# DA14531 register map
Vendor: Dialog; Series: DA14531; File version: 1.2
CPU: CM0 r1p0, little endian, MPU, FPU, 3 interrupt priority bits
Registers are 16-bit, read-write, reset 0x0 unless marked. A register's access mark holds for its fields unless they carry their own. Offsets are from the block's base; [hi:lo] are bit positions; {n}, {i} and the like mark numbered series.

## RFCU_POWER — RFCU_POWER registers
Base 0x40001200
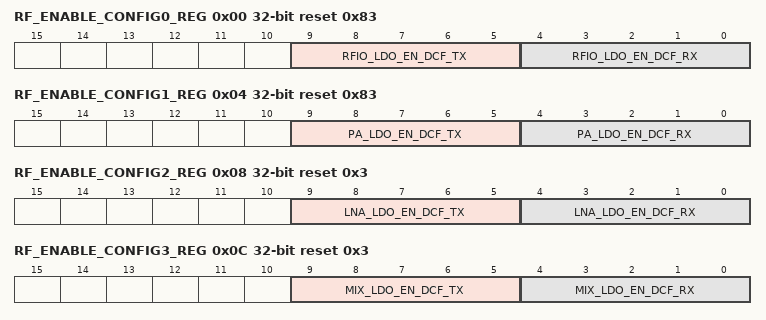
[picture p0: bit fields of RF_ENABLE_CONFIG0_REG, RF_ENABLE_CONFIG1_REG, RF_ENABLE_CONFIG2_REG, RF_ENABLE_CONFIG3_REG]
0x00 RF_ENABLE_CONFIG0_REG 32-bit reset 0x83
  [9:5] RFIO_LDO_EN_DCF_TX, [4:0] RFIO_LDO_EN_DCF_RX
0x04 RF_ENABLE_CONFIG1_REG 32-bit reset 0x83
  [9:5] PA_LDO_EN_DCF_TX, [4:0] PA_LDO_EN_DCF_RX
0x08 RF_ENABLE_CONFIG2_REG 32-bit reset 0x3
  [9:5] LNA_LDO_EN_DCF_TX, [4:0] LNA_LDO_EN_DCF_RX
0x0C RF_ENABLE_CONFIG3_REG 32-bit reset 0x3
  [9:5] MIX_LDO_EN_DCF_TX, [4:0] MIX_LDO_EN_DCF_RX
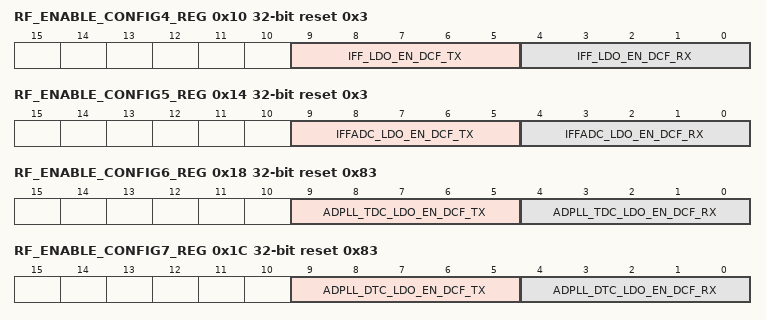
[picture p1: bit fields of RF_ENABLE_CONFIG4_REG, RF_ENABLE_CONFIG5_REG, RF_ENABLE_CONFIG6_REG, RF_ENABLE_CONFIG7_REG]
0x10 RF_ENABLE_CONFIG4_REG 32-bit reset 0x3
  [9:5] IFF_LDO_EN_DCF_TX, [4:0] IFF_LDO_EN_DCF_RX
0x14 RF_ENABLE_CONFIG5_REG 32-bit reset 0x3
  [9:5] IFFADC_LDO_EN_DCF_TX, [4:0] IFFADC_LDO_EN_DCF_RX
0x18 RF_ENABLE_CONFIG6_REG 32-bit reset 0x83
  [9:5] ADPLL_TDC_LDO_EN_DCF_TX, [4:0] ADPLL_TDC_LDO_EN_DCF_RX
0x1C RF_ENABLE_CONFIG7_REG 32-bit reset 0x83
  [9:5] ADPLL_DTC_LDO_EN_DCF_TX, [4:0] ADPLL_DTC_LDO_EN_DCF_RX
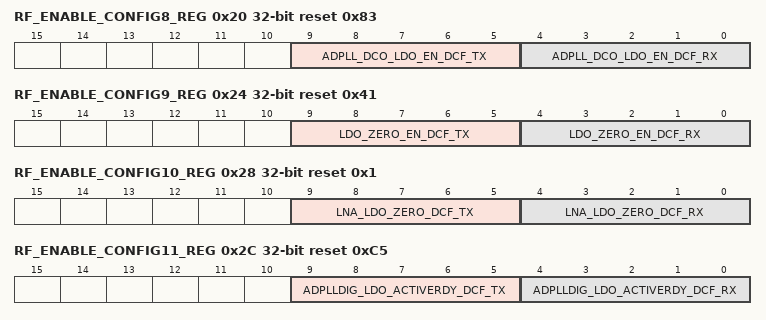
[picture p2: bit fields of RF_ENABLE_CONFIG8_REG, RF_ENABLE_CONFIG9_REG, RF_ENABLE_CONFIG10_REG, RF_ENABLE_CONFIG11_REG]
0x20 RF_ENABLE_CONFIG8_REG 32-bit reset 0x83
  [9:5] ADPLL_DCO_LDO_EN_DCF_TX, [4:0] ADPLL_DCO_LDO_EN_DCF_RX
0x24 RF_ENABLE_CONFIG9_REG 32-bit reset 0x41
  [9:5] LDO_ZERO_EN_DCF_TX, [4:0] LDO_ZERO_EN_DCF_RX
0x28 RF_ENABLE_CONFIG10_REG 32-bit reset 0x1
  [9:5] LNA_LDO_ZERO_DCF_TX, [4:0] LNA_LDO_ZERO_DCF_RX
0x2C RF_ENABLE_CONFIG11_REG 32-bit reset 0xC5
  [9:5] ADPLLDIG_LDO_ACTIVERDY_DCF_TX, [4:0] ADPLLDIG_LDO_ACTIVERDY_DCF_RX
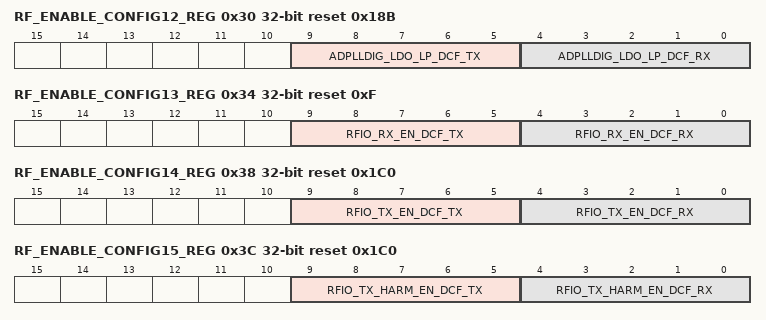
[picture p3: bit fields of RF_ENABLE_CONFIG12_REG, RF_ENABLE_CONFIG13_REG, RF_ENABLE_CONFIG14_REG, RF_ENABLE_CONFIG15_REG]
0x30 RF_ENABLE_CONFIG12_REG 32-bit reset 0x18B
  [9:5] ADPLLDIG_LDO_LP_DCF_TX, [4:0] ADPLLDIG_LDO_LP_DCF_RX
0x34 RF_ENABLE_CONFIG13_REG 32-bit reset 0xF
  [9:5] RFIO_RX_EN_DCF_TX, [4:0] RFIO_RX_EN_DCF_RX
0x38 RF_ENABLE_CONFIG14_REG 32-bit reset 0x1C0
  [9:5] RFIO_TX_EN_DCF_TX, [4:0] RFIO_TX_EN_DCF_RX
0x3C RF_ENABLE_CONFIG15_REG 32-bit reset 0x1C0
  [9:5] RFIO_TX_HARM_EN_DCF_TX, [4:0] RFIO_TX_HARM_EN_DCF_RX
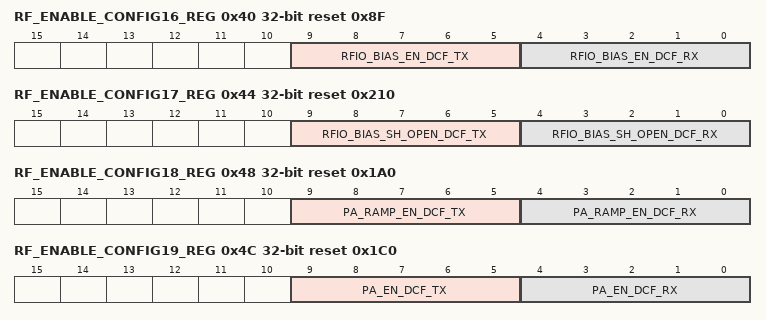
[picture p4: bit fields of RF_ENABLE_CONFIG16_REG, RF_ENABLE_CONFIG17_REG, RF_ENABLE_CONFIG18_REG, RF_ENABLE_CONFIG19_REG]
0x40 RF_ENABLE_CONFIG16_REG 32-bit reset 0x8F
  [9:5] RFIO_BIAS_EN_DCF_TX, [4:0] RFIO_BIAS_EN_DCF_RX
0x44 RF_ENABLE_CONFIG17_REG 32-bit reset 0x210
  [9:5] RFIO_BIAS_SH_OPEN_DCF_TX, [4:0] RFIO_BIAS_SH_OPEN_DCF_RX
0x48 RF_ENABLE_CONFIG18_REG 32-bit reset 0x1A0
  [9:5] PA_RAMP_EN_DCF_TX, [4:0] PA_RAMP_EN_DCF_RX
0x4C RF_ENABLE_CONFIG19_REG 32-bit reset 0x1C0
  [9:5] PA_EN_DCF_TX, [4:0] PA_EN_DCF_RX
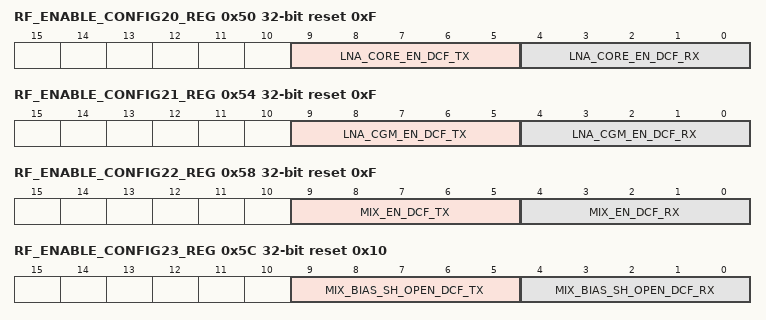
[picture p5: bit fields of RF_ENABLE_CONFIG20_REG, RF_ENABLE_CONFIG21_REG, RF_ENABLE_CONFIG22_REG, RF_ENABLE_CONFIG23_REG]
0x50 RF_ENABLE_CONFIG20_REG 32-bit reset 0xF
  [9:5] LNA_CORE_EN_DCF_TX, [4:0] LNA_CORE_EN_DCF_RX
0x54 RF_ENABLE_CONFIG21_REG 32-bit reset 0xF
  [9:5] LNA_CGM_EN_DCF_TX, [4:0] LNA_CGM_EN_DCF_RX
0x58 RF_ENABLE_CONFIG22_REG 32-bit reset 0xF
  [9:5] MIX_EN_DCF_TX, [4:0] MIX_EN_DCF_RX
0x5C RF_ENABLE_CONFIG23_REG 32-bit reset 0x10
  [9:5] MIX_BIAS_SH_OPEN_DCF_TX, [4:0] MIX_BIAS_SH_OPEN_DCF_RX
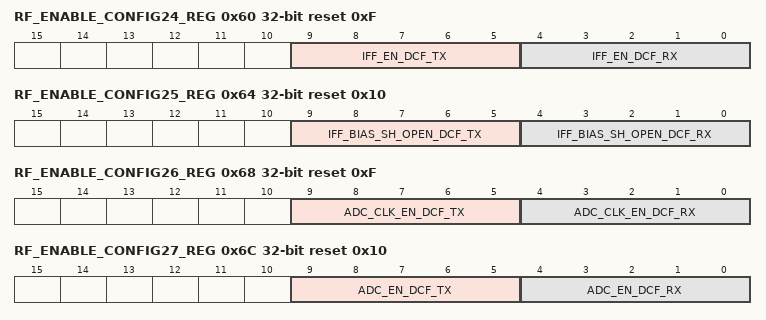
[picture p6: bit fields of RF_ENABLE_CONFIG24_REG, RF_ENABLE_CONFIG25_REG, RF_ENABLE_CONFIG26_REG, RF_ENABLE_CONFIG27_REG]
0x60 RF_ENABLE_CONFIG24_REG 32-bit reset 0xF
  [9:5] IFF_EN_DCF_TX, [4:0] IFF_EN_DCF_RX
0x64 RF_ENABLE_CONFIG25_REG 32-bit reset 0x10
  [9:5] IFF_BIAS_SH_OPEN_DCF_TX, [4:0] IFF_BIAS_SH_OPEN_DCF_RX
0x68 RF_ENABLE_CONFIG26_REG 32-bit reset 0xF
  [9:5] ADC_CLK_EN_DCF_TX, [4:0] ADC_CLK_EN_DCF_RX
0x6C RF_ENABLE_CONFIG27_REG 32-bit reset 0x10
  [9:5] ADC_EN_DCF_TX, [4:0] ADC_EN_DCF_RX
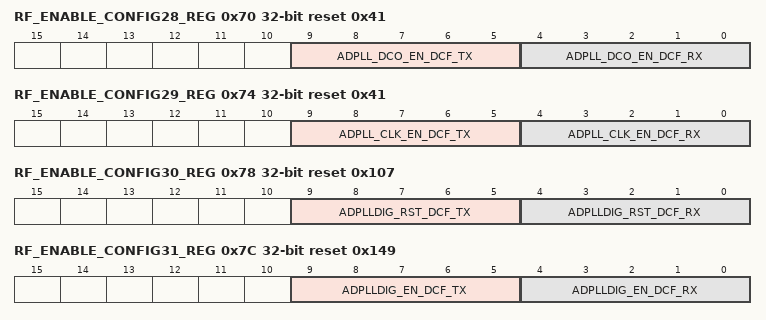
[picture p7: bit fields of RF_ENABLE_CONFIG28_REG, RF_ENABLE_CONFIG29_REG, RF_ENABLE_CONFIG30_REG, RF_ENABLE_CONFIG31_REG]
0x70 RF_ENABLE_CONFIG28_REG 32-bit reset 0x41
  [9:5] ADPLL_DCO_EN_DCF_TX, [4:0] ADPLL_DCO_EN_DCF_RX
0x74 RF_ENABLE_CONFIG29_REG 32-bit reset 0x41
  [9:5] ADPLL_CLK_EN_DCF_TX, [4:0] ADPLL_CLK_EN_DCF_RX
0x78 RF_ENABLE_CONFIG30_REG 32-bit reset 0x107
  [9:5] ADPLLDIG_RST_DCF_TX, [4:0] ADPLLDIG_RST_DCF_RX
0x7C RF_ENABLE_CONFIG31_REG 32-bit reset 0x149
  [9:5] ADPLLDIG_EN_DCF_TX, [4:0] ADPLLDIG_EN_DCF_RX
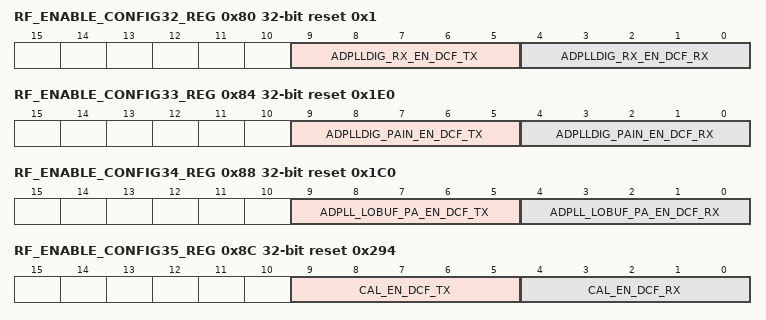
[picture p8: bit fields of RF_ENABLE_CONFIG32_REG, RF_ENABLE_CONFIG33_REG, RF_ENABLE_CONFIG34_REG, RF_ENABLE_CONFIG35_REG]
0x80 RF_ENABLE_CONFIG32_REG 32-bit reset 0x1
  [9:5] ADPLLDIG_RX_EN_DCF_TX, [4:0] ADPLLDIG_RX_EN_DCF_RX
0x84 RF_ENABLE_CONFIG33_REG 32-bit reset 0x1E0
  [9:5] ADPLLDIG_PAIN_EN_DCF_TX, [4:0] ADPLLDIG_PAIN_EN_DCF_RX
0x88 RF_ENABLE_CONFIG34_REG 32-bit reset 0x1C0
  [9:5] ADPLL_LOBUF_PA_EN_DCF_TX, [4:0] ADPLL_LOBUF_PA_EN_DCF_RX
0x8C RF_ENABLE_CONFIG35_REG 32-bit reset 0x294
  [9:5] CAL_EN_DCF_TX, [4:0] CAL_EN_DCF_RX
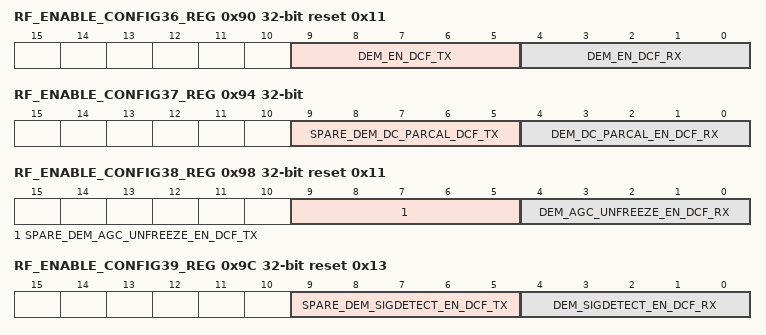
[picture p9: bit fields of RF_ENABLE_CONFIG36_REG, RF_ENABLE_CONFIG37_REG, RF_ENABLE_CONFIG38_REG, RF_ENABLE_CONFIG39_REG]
0x90 RF_ENABLE_CONFIG36_REG 32-bit reset 0x11
  [9:5] DEM_EN_DCF_TX, [4:0] DEM_EN_DCF_RX
0x94 RF_ENABLE_CONFIG37_REG 32-bit
  [9:5] SPARE_DEM_DC_PARCAL_DCF_TX, [4:0] DEM_DC_PARCAL_EN_DCF_RX
0x98 RF_ENABLE_CONFIG38_REG 32-bit reset 0x11
  [9:5] SPARE_DEM_AGC_UNFREEZE_EN_DCF_TX, [4:0] DEM_AGC_UNFREEZE_EN_DCF_RX
0x9C RF_ENABLE_CONFIG39_REG 32-bit reset 0x13
  [9:5] SPARE_DEM_SIGDETECT_EN_DCF_TX, [4:0] DEM_SIGDETECT_EN_DCF_RX
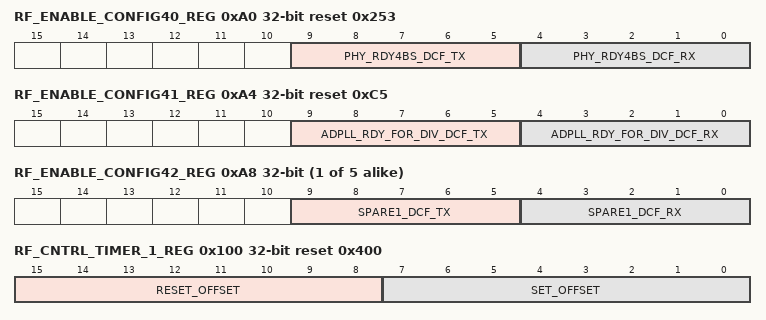
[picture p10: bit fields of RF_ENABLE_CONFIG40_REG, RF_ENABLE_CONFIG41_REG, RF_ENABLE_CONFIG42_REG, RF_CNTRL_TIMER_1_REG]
0xA0 RF_ENABLE_CONFIG40_REG 32-bit reset 0x253
  [9:5] PHY_RDY4BS_DCF_TX, [4:0] PHY_RDY4BS_DCF_RX
0xA4 RF_ENABLE_CONFIG41_REG 32-bit reset 0xC5
  [9:5] ADPLL_RDY_FOR_DIV_DCF_TX, [4:0] ADPLL_RDY_FOR_DIV_DCF_RX
{0x0+4i} RF_ENABLE_CONFIG{i}_REG 32-bit (i=42..46)
  [9:5] SPARE{i-41}_DCF_TX, [4:0] SPARE{i-41}_DCF_RX
0x100 RF_CNTRL_TIMER_1_REG 32-bit reset 0x400
  [15:8] RESET_OFFSET, [7:0] SET_OFFSET
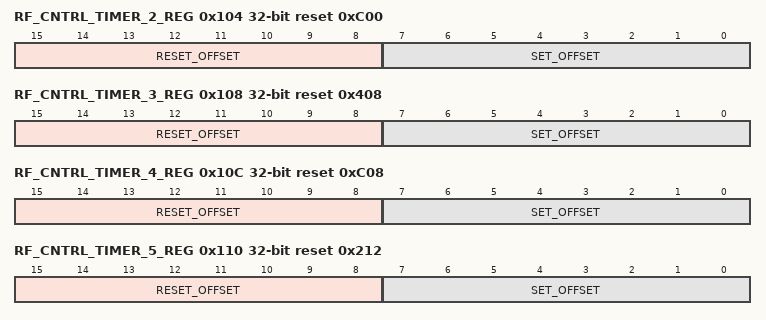
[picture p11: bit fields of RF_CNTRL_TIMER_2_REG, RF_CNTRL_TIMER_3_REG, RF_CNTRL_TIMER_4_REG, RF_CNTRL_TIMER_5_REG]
0x104 RF_CNTRL_TIMER_2_REG 32-bit reset 0xC00
  [15:8] RESET_OFFSET, [7:0] SET_OFFSET
0x108 RF_CNTRL_TIMER_3_REG 32-bit reset 0x408
  [15:8] RESET_OFFSET, [7:0] SET_OFFSET
0x10C RF_CNTRL_TIMER_4_REG 32-bit reset 0xC08
  [15:8] RESET_OFFSET, [7:0] SET_OFFSET
0x110 RF_CNTRL_TIMER_5_REG 32-bit reset 0x212
  [15:8] RESET_OFFSET, [7:0] SET_OFFSET
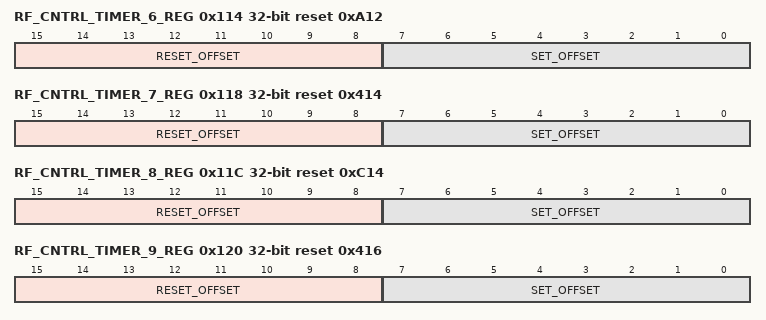
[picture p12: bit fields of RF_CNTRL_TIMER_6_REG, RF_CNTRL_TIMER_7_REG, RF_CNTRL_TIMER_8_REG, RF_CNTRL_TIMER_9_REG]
0x114 RF_CNTRL_TIMER_6_REG 32-bit reset 0xA12
  [15:8] RESET_OFFSET, [7:0] SET_OFFSET
0x118 RF_CNTRL_TIMER_7_REG 32-bit reset 0x414
  [15:8] RESET_OFFSET, [7:0] SET_OFFSET
0x11C RF_CNTRL_TIMER_8_REG 32-bit reset 0xC14
  [15:8] RESET_OFFSET, [7:0] SET_OFFSET
0x120 RF_CNTRL_TIMER_9_REG 32-bit reset 0x416
  [15:8] RESET_OFFSET, [7:0] SET_OFFSET
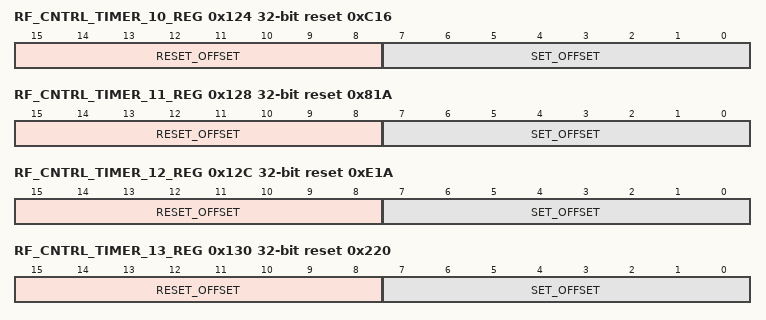
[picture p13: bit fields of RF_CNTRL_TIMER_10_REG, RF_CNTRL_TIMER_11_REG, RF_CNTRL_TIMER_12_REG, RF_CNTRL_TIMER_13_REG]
0x124 RF_CNTRL_TIMER_10_REG 32-bit reset 0xC16
  [15:8] RESET_OFFSET, [7:0] SET_OFFSET
0x128 RF_CNTRL_TIMER_11_REG 32-bit reset 0x81A
  [15:8] RESET_OFFSET, [7:0] SET_OFFSET
0x12C RF_CNTRL_TIMER_12_REG 32-bit reset 0xE1A
  [15:8] RESET_OFFSET, [7:0] SET_OFFSET
0x130 RF_CNTRL_TIMER_13_REG 32-bit reset 0x220
  [15:8] RESET_OFFSET, [7:0] SET_OFFSET
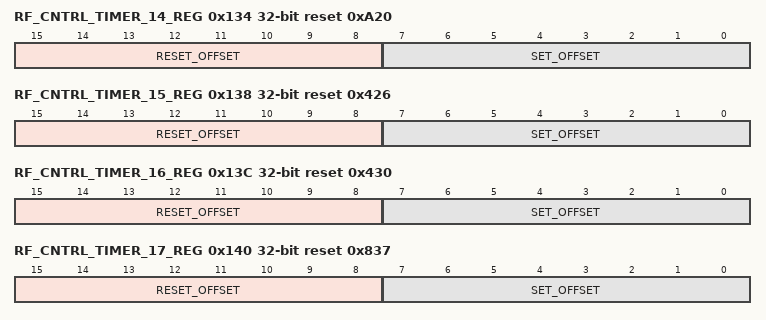
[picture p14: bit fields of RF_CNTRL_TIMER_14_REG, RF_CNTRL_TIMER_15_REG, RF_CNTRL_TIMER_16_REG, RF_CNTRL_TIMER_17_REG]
0x134 RF_CNTRL_TIMER_14_REG 32-bit reset 0xA20
  [15:8] RESET_OFFSET, [7:0] SET_OFFSET
0x138 RF_CNTRL_TIMER_15_REG 32-bit reset 0x426
  [15:8] RESET_OFFSET, [7:0] SET_OFFSET
0x13C RF_CNTRL_TIMER_16_REG 32-bit reset 0x430
  [15:8] RESET_OFFSET, [7:0] SET_OFFSET
0x140 RF_CNTRL_TIMER_17_REG 32-bit reset 0x837
  [15:8] RESET_OFFSET, [7:0] SET_OFFSET
0x144 RF_CNTRL_TIMER_18_REG 32-bit reset 0x846
  [15:8] RESET_OFFSET, [7:0] SET_OFFSET
0x148 RF_CNTRL_TIMER_19_REG 32-bit reset 0x850
  [15:8] RESET_OFFSET, [7:0] SET_OFFSET
0x14C RF_CNTRL_TIMER_20_REG 32-bit reset 0x125A
  [15:8] RESET_OFFSET, [7:0] SET_OFFSET
{0xFC+4i} RF_CNTRL_TIMER_{i}_REG 32-bit (i=21..31)
  [15:8] RESET_OFFSET, [7:0] SET_OFFSET
0x180 RF_ALWAYS_EN1_REG 32-bit (reset mask 0x7FFFFFFF)
  [31] ALW_EN_ADPLLDIG_EN, [30] ALW_EN_ADPLLDIG_RST, [29] ALW_EN_ADPLL_CLK_EN, [28] ALW_EN_ADPLL_DCO_EN, [27] ALW_EN_ADC_EN, [26] ALW_EN_ADC_CLK_EN, [25] ALW_EN_IFF_BIAS_SH_OPEN, [24] ALW_EN_IFF_EN, [23] ALW_EN_MIX_BIAS_SH_OPEN, [22] ALW_EN_MIX_EN, [21] ALW_EN_LNA_CGM_EN, [20] ALW_EN_LNA_CORE_EN, [19] ALW_EN_PA_EN, [18] ALW_EN_PA_RAMP_EN, [17] ALW_EN_RFIO_BIAS_SH_OPEN, [16] ALW_EN_RFIO_BIAS_EN, [15] ALW_EN_RFIO_TX_HARM_EN, [14] ALW_EN_RFIO_TX_EN, [13] ALW_EN_RFIO_RX_EN, [12] ALW_EN_ADPLLDIG_LDO_LP, [11] ALW_EN_ADPLLDIG_LDO_ACTIVERDY, [10] ALW_EN_LNA_LDO_ZERO, [9] ALW_EN_LDO_ZERO_EN, [8] ALW_EN_ADPLL_DCO_LDO_EN, [7] ALW_EN_ADPLL_DTC_LDO_EN, [6] ALW_EN_ADPLL_TDC_LDO_EN, [5] ALW_EN_IFFADC_LDO_EN, [4] ALW_EN_IFF_LDO_EN, [3] ALW_EN_MIX_LDO_EN, [2] ALW_EN_LNA_LDO_EN, [1] ALW_EN_PA_LDO_EN, [0] ALW_EN_RFIO_LDO_EN
0x184 RF_ALWAYS_EN2_REG 32-bit
  [n+9] ALW_EN_SPARE{n} (n=1..5), [9] ALW_EN_ADPLL_RDY_FOR_DIV, [8] ALW_EN_PHY_RDY4BS, [7] ALW_EN_DEM_SIGDETECT_EN, [6] ALW_EN_DEM_AGC_UNFREEZE_EN, [5] ALW_EN_DEM_DC_PARCAL_EN, [4] ALW_EN_DEM_EN, [3] ALW_EN_CAL_EN, [2] ALW_EN_ADPLL_LOBUF_PA_EN, [1] ALW_EN_ADPLL_PAIN_EN, [0] ALW_EN_ADPLLDIG_RX_EN
0x188 RF_PORT_EN_REG 32-bit
  [2n+1] RF_PORT{n}_TX (n=0..4), [2n] RF_PORT{n}_RX (n=0..4)
0x18C RF_PORT_POL_REG 32-bit
  [n] RF_PORT{n}_POL (n=0..4)
